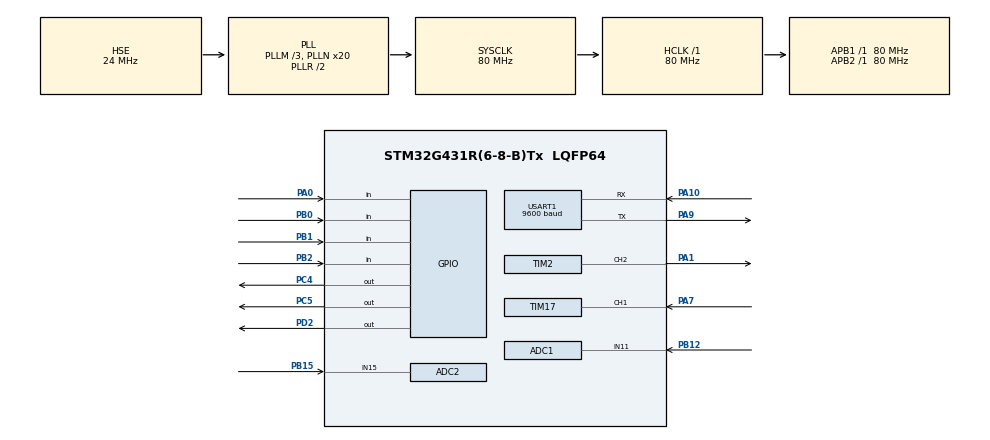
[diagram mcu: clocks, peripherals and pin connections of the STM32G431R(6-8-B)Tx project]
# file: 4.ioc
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ADC1.Channel-0\#ChannelRegularConversion=ADC_CHANNEL_11
ADC1.ClockPrescaler=ADC_CLOCK_SYNC_PCLK_DIV4
ADC1.ContinuousConvMode=ENABLE
ADC1.DMAContinuousRequests=ENABLE
ADC1.NbrOfConversionFlag=1
ADC1.OffsetNumber-0\#ChannelRegularConversion=ADC_OFFSET_NONE
ADC1.Rank-0\#ChannelRegularConversion=1
ADC1.SamplingTime-0\#ChannelRegularConversion=ADC_SAMPLETIME_2CYCLES_5
ADC1.master=1
ADC2.Channel-0\#ChannelRegularConversion=ADC_CHANNEL_15
ADC2.ClockPrescaler=ADC_CLOCK_SYNC_PCLK_DIV4
ADC2.ContinuousConvMode=ENABLE
ADC2.DMAContinuousRequests=ENABLE
ADC2.NbrOfConversionFlag=1
ADC2.OffsetNumber-0\#ChannelRegularConversion=ADC_OFFSET_NONE
ADC2.Rank-0\#ChannelRegularConversion=1
ADC2.SamplingTime-0\#ChannelRegularConversion=ADC_SAMPLETIME_2CYCLES_5
Dma.ADC1.1.Direction=DMA_PERIPH_TO_MEMORY
Dma.ADC1.1.EventEnable=DISABLE
Dma.ADC1.1.Instance=DMA1_Channel2
Dma.ADC1.1.MemDataAlignment=DMA_MDATAALIGN_WORD
Dma.ADC1.1.MemInc=DMA_MINC_ENABLE
Dma.ADC1.1.Mode=DMA_CIRCULAR
Dma.ADC1.1.PeriphDataAlignment=DMA_PDATAALIGN_WORD
Dma.ADC1.1.PeriphInc=DMA_PINC_DISABLE
Dma.ADC1.1.Polarity=HAL_DMAMUX_REQ_GEN_RISING
Dma.ADC1.1.Priority=DMA_PRIORITY_HIGH
Dma.ADC1.1.RequestNumber=1
Dma.ADC1.1.SignalID=NONE
Dma.ADC1.1.SyncEnable=DISABLE
Dma.ADC1.1.SyncPolarity=HAL_DMAMUX_SYNC_NO_EVENT
Dma.ADC1.1.SyncRequestNumber=1
Dma.ADC1.1.SyncSignalID=NONE
Dma.ADC2.2.Direction=DMA_PERIPH_TO_MEMORY
Dma.ADC2.2.EventEnable=DISABLE
Dma.ADC2.2.Instance=DMA1_Channel3
Dma.ADC2.2.MemDataAlignment=DMA_MDATAALIGN_WORD
Dma.ADC2.2.MemInc=DMA_MINC_ENABLE
Dma.ADC2.2.Mode=DMA_CIRCULAR
Dma.ADC2.2.PeriphDataAlignment=DMA_PDATAALIGN_WORD
Dma.ADC2.2.PeriphInc=DMA_PINC_DISABLE
Dma.ADC2.2.Polarity=HAL_DMAMUX_REQ_GEN_RISING
Dma.ADC2.2.Priority=DMA_PRIORITY_HIGH
Dma.ADC2.2.RequestNumber=1
Dma.ADC2.2.SignalID=NONE
Dma.ADC2.2.SyncEnable=DISABLE
Dma.ADC2.2.SyncPolarity=HAL_DMAMUX_SYNC_NO_EVENT
Dma.ADC2.2.SyncRequestNumber=1
Dma.ADC2.2.SyncSignalID=NONE
Dma.Request0=USART1_RX
Dma.Request1=ADC1
Dma.Request2=ADC2
Dma.USART1_RX.0.Direction=DMA_PERIPH_TO_MEMORY
Dma.USART1_RX.0.EventEnable=DISABLE
Dma.USART1_RX.0.Instance=DMA1_Channel1
Dma.USART1_RX.0.MemDataAlignment=DMA_MDATAALIGN_WORD
Dma.USART1_RX.0.MemInc=DMA_MINC_ENABLE
Dma.USART1_RX.0.Mode=DMA_NORMAL
Dma.USART1_RX.0.PeriphDataAlignment=DMA_PDATAALIGN_WORD
Dma.USART1_RX.0.PeriphInc=DMA_PINC_DISABLE
Dma.USART1_RX.0.Polarity=HAL_DMAMUX_REQ_GEN_RISING
Dma.USART1_RX.0.Priority=DMA_PRIORITY_HIGH
Dma.USART1_RX.0.RequestNumber=1
Dma.USART1_RX.0.SignalID=NONE
Dma.USART1_RX.0.SyncEnable=DISABLE
Dma.USART1_RX.0.SyncPolarity=HAL_DMAMUX_SYNC_NO_EVENT
Dma.USART1_RX.0.SyncRequestNumber=1
Dma.USART1_RX.0.SyncSignalID=NONE
Mcu.Family=STM32G4
Mcu.Name=STM32G431R(6-8-B)Tx
Mcu.Package=LQFP64
NVIC.ADC1_2_IRQn=true\:2\:0\:true\:false\:true\:true\:true\:true
NVIC.DMA1_Channel1_IRQn=true\:0\:0\:false\:false\:true\:false\:true\:true
NVIC.DMA1_Channel2_IRQn=true\:0\:0\:false\:false\:true\:false\:true\:true
NVIC.DMA1_Channel3_IRQn=true\:0\:0\:false\:false\:true\:false\:true\:true
NVIC.PriorityGroup=NVIC_PRIORITYGROUP_4
NVIC.TIM1_TRG_COM_TIM17_IRQn=true\:0\:0\:false\:false\:true\:true\:true\:true
NVIC.TIM1_UP_TIM16_IRQn=true\:0\:0\:false\:false\:true\:true\:true\:true
PA0.Signal=GPIO_Input
PA1.Signal=S_TIM2_CH2
PA10.Mode=Asynchronous
PA10.Signal=USART1_RX
PA7.Signal=S_TIM17_CH1
PA9.Mode=Asynchronous
PA9.Signal=USART1_TX
PB0.Signal=GPIO_Input
PB1.Signal=GPIO_Input
PB12.Mode=IN11-Single-Ended
PB12.Signal=ADC1_IN11
PB15.Mode=IN15-Single-Ended
PB15.Signal=ADC2_IN15
PB2.Signal=GPIO_Input
PC4.Signal=GPIO_Output
PC5.Signal=GPIO_Output
PD2.Signal=GPIO_Output
PF0-OSC_IN.Mode=HSE-External-Oscillator
PF0-OSC_IN.Signal=RCC_OSC_IN
PF1-OSC_OUT.Mode=HSE-External-Oscillator
PF1-OSC_OUT.Signal=RCC_OSC_OUT
ProjectManager.HeapSize=0x200
ProjectManager.StackSize=0x400
ProjectManager.TargetToolchain=MDK-ARM V5.32
RCC.ADC12Freq_Value=80000000
RCC.AHBFreq_Value=80000000
RCC.APB1Freq_Value=80000000
RCC.APB1TimFreq_Value=80000000
RCC.APB2Freq_Value=80000000
RCC.APB2TimFreq_Value=80000000
RCC.CortexFreq_Value=80000000
RCC.EXTERNAL_CLOCK_VALUE=12288000
RCC.HCLKFreq_Value=80000000
RCC.HSE_VALUE=24000000
RCC.HSI48_VALUE=48000000
RCC.HSI_VALUE=16000000
RCC.LSE_VALUE=32768
RCC.PLLM=RCC_PLLM_DIV3
RCC.PLLN=20
RCC.PLLSourceVirtual=RCC_PLLSOURCE_HSE
RCC.SYSCLKFreq_VALUE=80000000
RCC.SYSCLKSource=RCC_SYSCLKSOURCE_PLLCLK
RCC.USBFreq_Value=80000000
RCC.VCOOutputFreq_Value=160000000
SH.S_TIM17_CH1.0=TIM17_CH1,Input_Capture1_from_TI1
SH.S_TIM2_CH2.0=TIM2_CH2,PWM Generation2 CH2
TIM1.PeriodNoDither=99
TIM1.Prescaler=7999
TIM17.Channel=TIM_CHANNEL_1
TIM17.Prescaler=79
TIM2.Channel-PWM\ Generation2\ CH2=TIM_CHANNEL_2
TIM2.PeriodNoDither=99
TIM2.Prescaler=799
USART1.BaudRate=9600
USART1.VirtualMode-Asynchronous=VM_ASYNC
VP_SYS_VS_DBSignals.Mode=DisableDeadBatterySignals
VP_TIM17_VS_ClockSourceINT.Mode=Enable_Timer
VP_TIM1_VS_ClockSourceINT.Mode=Internal
board=custom

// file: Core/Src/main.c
/* USER CODE BEGIN Header */
/**
  ******************************************************************************
  * @file           : main.c
  * @brief          : Main program body
  ******************************************************************************
  * @attention
  *
  * Copyright (c) 2025 STMicroelectronics.
  * All rights reserved.
  *
  * This software is licensed under terms that can be found in the LICENSE file
  * in the root directory of this software component.
  * If no LICENSE file comes with this software, it is provided AS-IS.
  *
  ******************************************************************************
  */
/* USER CODE END Header */
#include "main.h"
#include "adc.h"
#include "dma.h"
#include "tim.h"
#include "usart.h"
#include "gpio.h"

/* USER CODE BEGIN Includes */

#include "BSP.h"

/* USER CODE END Includes */

void SystemClock_Config(void);

int main(void)
{

  /* MCU Configuration--------------------------------------------------------*/

  /* Reset of all peripherals, Initializes the Flash interface and the Systick. */
  HAL_Init();

  /* Configure the system clock */
  SystemClock_Config();

  /* Initialize all configured peripherals */
  MX_GPIO_Init();
  MX_DMA_Init();
  MX_TIM1_Init();
  MX_USART1_UART_Init();
  MX_TIM2_Init();
  MX_TIM17_Init();
  MX_ADC1_Init();
  MX_ADC2_Init();
  /* USER CODE BEGIN 2 */

	HAL_TIM_Base_Start_IT(&htim1);
	HAL_TIM_PWM_Start(&htim2 ,TIM_CHANNEL_2);
	TIM2 -> CCR2 = 50;
	HAL_TIM_IC_Start_IT(&htim17,TIM_CHANNEL_1);
	HAL_ADC_Start_DMA(&hadc1,(uint32_t *)&dma_buff_1,30);
	HAL_ADC_Start_DMA(&hadc2,(uint32_t *)&dma_buff_2,30);

	system_init();

  /* USER CODE END 2 */

  /* Infinite loop */
  /* USER CODE BEGIN WHILE */
  while (1)
  {
		lcd_text();
		key_show();
		adc_show();
    /* USER CODE END WHILE */

  }
}

void SystemClock_Config(void)
{
  RCC_OscInitTypeDef RCC_OscInitStruct = {0};
  RCC_ClkInitTypeDef RCC_ClkInitStruct = {0};

  /** Configure the main internal regulator output voltage
  */
  HAL_PWREx_ControlVoltageScaling(PWR_REGULATOR_VOLTAGE_SCALE1);

  /** Initializes the RCC Oscillators according to the specified parameters
  * in the RCC_OscInitTypeDef structure.
  */
  RCC_OscInitStruct.OscillatorType = RCC_OSCILLATORTYPE_HSE;
  RCC_OscInitStruct.HSEState = RCC_HSE_ON;
  RCC_OscInitStruct.PLL.PLLState = RCC_PLL_ON;
  RCC_OscInitStruct.PLL.PLLSource = RCC_PLLSOURCE_HSE;
  RCC_OscInitStruct.PLL.PLLM = RCC_PLLM_DIV3;
  RCC_OscInitStruct.PLL.PLLN = 20;
  RCC_OscInitStruct.PLL.PLLP = RCC_PLLP_DIV2;
  RCC_OscInitStruct.PLL.PLLQ = RCC_PLLQ_DIV2;
  RCC_OscInitStruct.PLL.PLLR = RCC_PLLR_DIV2;
  if (HAL_RCC_OscConfig(&RCC_OscInitStruct) != HAL_OK)
  {
    Error_Handler();
  }

  /** Initializes the CPU, AHB and APB buses clocks
  */
  RCC_ClkInitStruct.ClockType = RCC_CLOCKTYPE_HCLK|RCC_CLOCKTYPE_SYSCLK
                              |RCC_CLOCKTYPE_PCLK1|RCC_CLOCKTYPE_PCLK2;
  RCC_ClkInitStruct.SYSCLKSource = RCC_SYSCLKSOURCE_PLLCLK;
  RCC_ClkInitStruct.AHBCLKDivider = RCC_SYSCLK_DIV1;
  RCC_ClkInitStruct.APB1CLKDivider = RCC_HCLK_DIV1;
  RCC_ClkInitStruct.APB2CLKDivider = RCC_HCLK_DIV1;

  if (HAL_RCC_ClockConfig(&RCC_ClkInitStruct, FLASH_LATENCY_2) != HAL_OK)
  {
    Error_Handler();
  }
}

void Error_Handler(void)
{
  __disable_irq();
  while (1)
  {
  }
}
